# R7FA2A2AD register map
Vendor: Renesas Electronics Corporation; Series: RA2A2; File version: 1.20.02
CPU: CM23 r1p0, little endian, MPU, no FPU, VTOR, 2 interrupt priority bits, 32 interrupts
Registers are 8-bit, read-write, reset 0x0 unless marked. A register's access mark holds for its fields unless they carry their own. Offsets are from the block's base; [hi:lo] are bit positions; 'fields as' and 'values as' point back to an identical list.

## IWDT — Independent Watchdog Timer
Base 0x40044400
0x00 IWDTRR reset 0xFF — IWDT Refresh Register
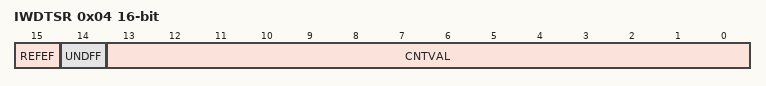
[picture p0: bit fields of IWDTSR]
0x04 IWDTSR 16-bit — IWDT Status Register
  [15] REFEF — Refresh Error Flag
    0=No refresh error occurred; 1=Refresh error occurred
  [14] UNDFF — Underflow Flag
    0=No underflow occurred; 1=Underflow occurred
  [13:0] CNTVAL ro — Down-counter Value

## CAC — Clock Frequency Accuracy Measurement Circuit
Base 0x40044600
0x00 CACR0 — CAC Control Register 0
  [0] CFME — Clock Frequency Measurement Enable
    0=Disable; 1=Enable
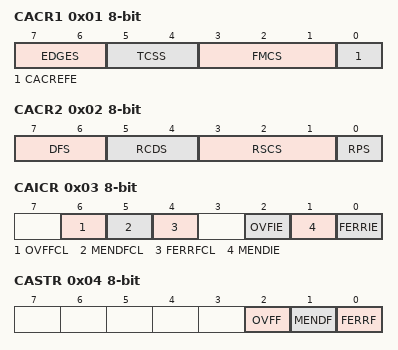
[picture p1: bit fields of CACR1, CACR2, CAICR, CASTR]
0x01 CACR1 — CAC Control Register 1
  [7:6] EDGES — Valid Edge Select
    0=Rising edge; 1=Falling edge; 2=Both rising and falling edges; 3=Setting prohibited
  [5:4] TCSS — Timer Count Clock Source Select
    0=No division; 1=1/4 clock; 2=1/8 clock; 3=1/32 clock
  [3:1] FMCS — Measurement Target Clock Select
    0=Main clock oscillator; 1=Sub-clock oscillator; 2=HOCO clock; 3=MOCO clock; 4=LOCO clock; 5=Peripheral module clock B (PCLKB); 6=IWDT-dedicated clock; 7=Setting prohibited
  [0] CACREFE — CACREF Pin Input Enable
    0=Disable; 1=Enable
0x02 CACR2 — CAC Control Register 2
  [7:6] DFS — Digital Filter Select
    0=Disable digital filtering; 1=Use sampling clock for the digital filter as the frequency measuring clock; 2=Use sampling clock for the digital filter as the frequency measuring clock divided by 4; 3=Use sampling clock for the digital filter as the frequency measuring clock divided by 16
  [5:4] RCDS — Measurement Reference Clock Frequency Division Ratio Select
    0=1/32 clock; 1=1/128 clock; 2=1/1024 clock; 3=1/8192 clock
  [3:1] RSCS — Measurement Reference Clock Select
    values as CACR1.FMCS
  [0] RPS — Reference Signal Select
    0=CACREF pin input; 1=Internal clock (internally generated signal)
0x03 CAICR — CAC Interrupt Control Register
  [6] OVFFCL wo — OVFF Clear
    0=No effect; 1=The CASTR.OVFF flag is cleared
  [5] MENDFCL wo — MENDF Clear
    0=No effect; 1=The CASTR.MENDF flag is cleared
  [4] FERRFCL wo — FERRF Clear
    0=No effect; 1=The CASTR.FERRF flag is cleared
  [2] OVFIE — Overflow Interrupt Request Enable
    0=Disable; 1=Enable
  [1] MENDIE — Measurement End Interrupt Request Enable
    0=Disable; 1=Enable
  [0] FERRIE — Frequency Error Interrupt Request Enable
    0=Disable; 1=Enable
0x04 CASTR ro — CAC Status Register
  [2] OVFF — Overflow Flag
    0=Counter has not overflowed; 1=Counter overflowed
  [1] MENDF — Measurement End Flag
    0=Measurement is in progress; 1=Measurement ended
  [0] FERRF — Frequency Error Flag
    0=Clock frequency is within the allowable range; 1=Clock frequency has deviated beyond the allowable range (frequency error)
0x06 CAULVR 16-bit — CAC Upper-Limit Value Setting Register
0x08 CALLVR 16-bit — CAC Lower-Limit Value Setting Register
0x0A CACNTBR 16-bit ro — CAC Counter Buffer Register

## MSTP — Module Stop Control A, B, C, D
Base 0x40047000
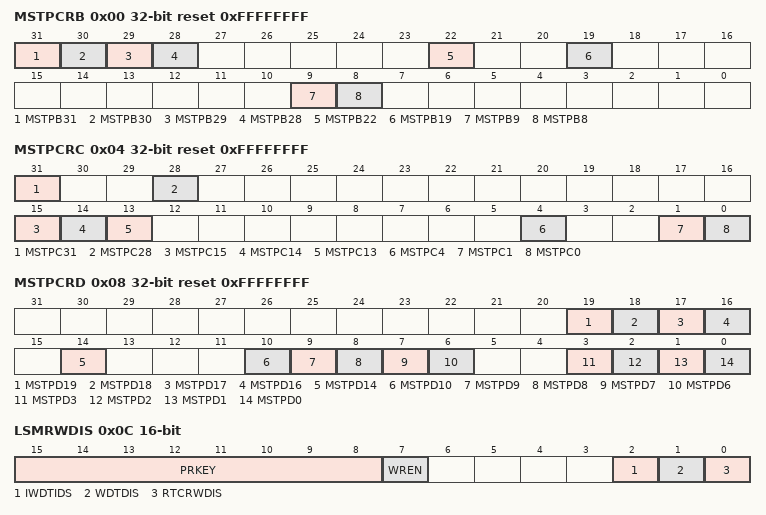
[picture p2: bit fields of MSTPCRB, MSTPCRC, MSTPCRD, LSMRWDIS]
0x00 MSTPCRB 32-bit reset 0xFFFFFFFF — Module Stop Control Register B
  [all] fields
    0=Cancel the module-stop state; 1=Enter the module-stop state
  [31] MSTPB31 — Serial Communication Interface 0 Module Stop
  [30] MSTPB30 — Serial Communication Interface 1 Module Stop
  [29] MSTPB29 — Serial Communication Interface 2 Module Stop
  [28] MSTPB28 — Serial Communication Interface 3 Module Stop
  [22] MSTPB22 — Serial Communication Interface 9 Module Stop
  [19] MSTPB19 — Serial Peripheral Interface 0 Module Stop
  [9] MSTPB9 — I2C Bus Interface 0 Module Stop
  [8] MSTPB8 — I2C Bus Interface 1 Module Stop
0x04 MSTPCRC 32-bit reset 0xFFFFFFFF — Module Stop Control Register C
  [all] fields
    values as the fields of MSTPCRB
  [31] MSTPC31 — AES Module Stop
  [28] MSTPC28 — True Random Number Generator Module Stop
  [15] MSTPC15 — 32-bit Multiply-Accumulator Module Stop
  [14] MSTPC14 — Event Link Controller Module Stop
  [13] MSTPC13 — Data Operation Circuit Module Stop
  [4] MSTPC4 — Segment LCD Controller Module Stop
  [1] MSTPC1 — Cyclic Redundancy Check Calculator Module Stop
  [0] MSTPC0 — Clock Frequency Accuracy Measurement Circuit Module Stop
0x08 MSTPCRD 32-bit reset 0xFFFFFFFF — Module Stop Control Register D
  [all] fields
    values as the fields of MSTPCRB
  [19] MSTPD19 — 16-bit Low Power Asynchronous General Purpose Timer 0 Module Stop
  [18] MSTPD18 — 16-bit Low Power Asynchronous General Purpose Timer 1 Module Stop
  [17] MSTPD17 — 24-bit Sigma-Delta A/D Converter Module Stop
  [16] MSTPD16 — 12-bit A/D Converter Module Stop
  [14] MSTPD14 — Port Output Enable for GPT Module Stop
  [10] MSTPD10 — 16-bit Low Power Asynchronous General Purpose Timer 4 Module Stop
  [9] MSTPD9 — 16-bit Low Power Asynchronous General Purpose Timer 5 Module Stop
  [8] MSTPD8 — 16-bit Low Power Asynchronous General Purpose Timer 6 Module Stop
  [7] MSTPD7 — 16-bit Low Power Asynchronous General Purpose Timer 7 Module Stop
  [6] MSTPD6 — General PWM Timer 164 to 169 and PWM Delay Generation Circuit Module Stop
  [3] MSTPD3 — 32-bit Low Power Asynchronous General Purpose Timer 0 Module Stop
  [2] MSTPD2 — 32-bit Low Power Asynchronous General Purpose Timer 1 Module Stop
  [1] MSTPD1 — 16-bit Low Power Asynchronous General Purpose Timer 2 Module Stop
  [0] MSTPD0 — 16-bit Low Power Asynchronous General Purpose Timer 3 Module Stop
0x0C LSMRWDIS 16-bit — Low Speed Module R/W Disable Control Register
  [15:8] PRKEY wo — LSMRWDIS Key Code
  [7] WREN — Write Enable for bits [2:0]
    0=Write protect for bits [2:0]; 1=Write enable for bits [2:0]
  [2] IWDTIDS — IWDT Register Clock Control
    0=IWDT operates as normal; 1=Stop the IWDT register R/W clock
  [1] WDTDIS — WDT Operate Clock Control
    0=WDT operates as normal; 1=Stop the WDT clock and register R/W clock
  [0] RTCRWDIS — RTC Register R/W Enable Control
    0=RTC register R/W clock always on; 1=RTC register R/W clock stops
